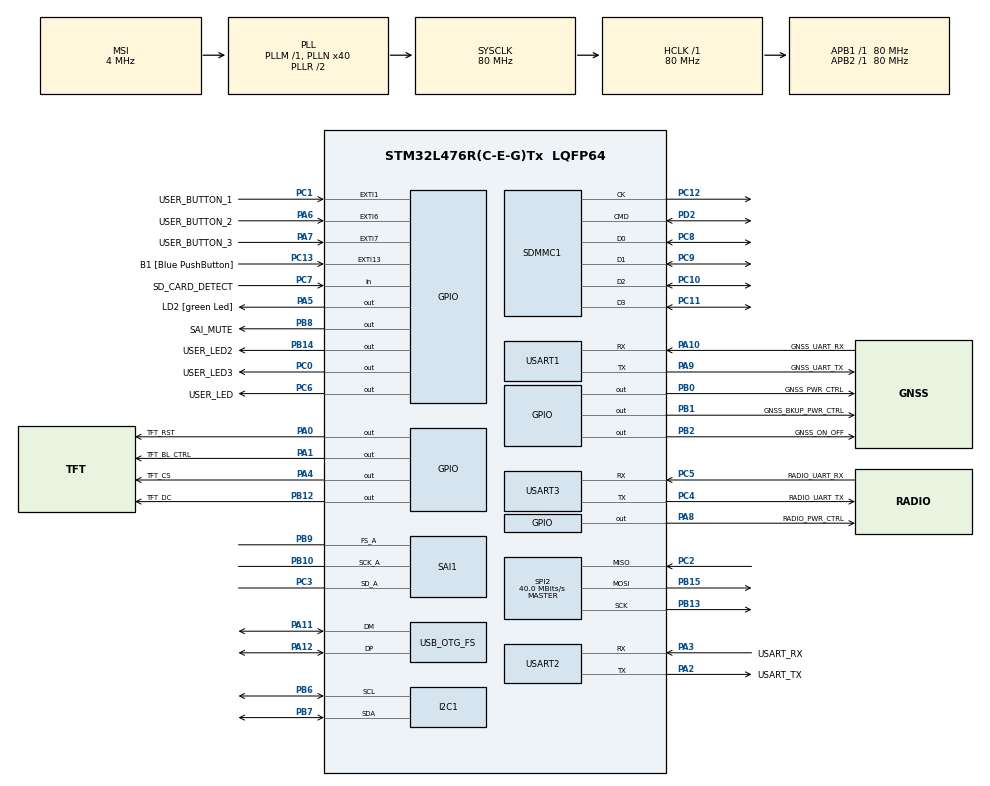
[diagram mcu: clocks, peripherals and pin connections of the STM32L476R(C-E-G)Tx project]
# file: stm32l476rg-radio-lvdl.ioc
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Dma.Request0=SAI1_A
Dma.Request1=SPI2_TX
Dma.Request2=SDMMC1_RX
Dma.SAI1_A.0.Direction=DMA_MEMORY_TO_PERIPH
Dma.SAI1_A.0.Instance=DMA2_Channel1
Dma.SAI1_A.0.MemDataAlignment=DMA_MDATAALIGN_HALFWORD
Dma.SAI1_A.0.MemInc=DMA_MINC_ENABLE
Dma.SAI1_A.0.Mode=DMA_NORMAL
Dma.SAI1_A.0.PeriphDataAlignment=DMA_PDATAALIGN_HALFWORD
Dma.SAI1_A.0.PeriphInc=DMA_PINC_DISABLE
Dma.SAI1_A.0.Priority=DMA_PRIORITY_LOW
Dma.SDMMC1_RX.2.Direction=DMA_PERIPH_TO_MEMORY
Dma.SDMMC1_RX.2.Instance=DMA2_Channel4
Dma.SDMMC1_RX.2.MemDataAlignment=DMA_MDATAALIGN_WORD
Dma.SDMMC1_RX.2.MemInc=DMA_MINC_ENABLE
Dma.SDMMC1_RX.2.Mode=DMA_NORMAL
Dma.SDMMC1_RX.2.PeriphDataAlignment=DMA_PDATAALIGN_WORD
Dma.SDMMC1_RX.2.PeriphInc=DMA_PINC_DISABLE
Dma.SDMMC1_RX.2.Priority=DMA_PRIORITY_LOW
Dma.SPI2_TX.1.Direction=DMA_MEMORY_TO_PERIPH
Dma.SPI2_TX.1.Instance=DMA1_Channel5
Dma.SPI2_TX.1.MemDataAlignment=DMA_MDATAALIGN_BYTE
Dma.SPI2_TX.1.MemInc=DMA_MINC_ENABLE
Dma.SPI2_TX.1.Mode=DMA_NORMAL
Dma.SPI2_TX.1.PeriphDataAlignment=DMA_PDATAALIGN_BYTE
Dma.SPI2_TX.1.PeriphInc=DMA_PINC_DISABLE
Dma.SPI2_TX.1.Priority=DMA_PRIORITY_LOW
FATFS.BSP.number=1
FATFS._USE_LFN=2
FATFS0.BSP.STBoard=false
FATFS0.BSP.api=Unknown
FATFS0.BSP.instance=PC7
FATFS0.BSP.ip=GPIO
FATFS0.BSP.mode=Input
FATFS0.BSP.name=Detect_SDIO
FATFS0.BSP.solution=PC7
FREERTOS.Mutexes01=gnssDataLock,Dynamic,NULL,Depleted;uiDataLock,Dynamic,NULL,Depleted;debugLock,Dynamic,NULL,Depleted;sdCardAccessLock,Dynamic,NULL,Available
FREERTOS.Tasks01=mainTask,24,128,StartDefaultTask,Default,NULL,Dynamic,NULL,NULL;gnssTask,8,128,startGnssTask,Default,NULL,Dynamic,NULL,NULL;uiTask,40,3000,startUiTask,Default,NULL,Dynamic,NULL,NULL
FREERTOS.configMINIMAL_STACK_SIZE=128
FREERTOS.configTOTAL_HEAP_SIZE=20000
FREERTOS.configUSE_NEWLIB_REENTRANT=1
I2C1.Timing=0x10D19CE4
Mcu.Family=STM32L4
Mcu.Name=STM32L476R(C-E-G)Tx
Mcu.Package=LQFP64
NVIC.DMA1_Channel5_IRQn=true\:5\:0\:false\:false\:true\:true\:false\:true\:true
NVIC.DMA2_Channel1_IRQn=true\:5\:0\:false\:false\:true\:true\:false\:true\:true
NVIC.DMA2_Channel4_IRQn=true\:5\:0\:false\:false\:true\:true\:false\:true\:true
NVIC.EXTI15_10_IRQn=true\:5\:0\:false\:false\:true\:true\:true\:true\:true
NVIC.EXTI1_IRQn=true\:5\:0\:false\:false\:true\:true\:true\:true\:true
NVIC.EXTI9_5_IRQn=true\:5\:0\:false\:false\:true\:true\:true\:true\:true
NVIC.OTG_FS_IRQn=true\:5\:0\:false\:false\:true\:true\:false\:true\:true
NVIC.PriorityGroup=NVIC_PRIORITYGROUP_4
NVIC.TIM1_UP_TIM16_IRQn=true\:15\:0\:false\:false\:true\:false\:false\:true\:true
NVIC.TimeBase=TIM1_UP_TIM16_IRQn
NVIC.TimeBaseIP=TIM1
PA0.GPIO_Label=TFT_RST
PA0.Signal=GPIO_Output
PA1.GPIO_Label=TFT_BL_CTRL
PA1.Signal=GPIO_Output
PA10.GPIO_Label=GNSS_UART_RX
PA10.Mode=Asynchronous
PA10.Signal=USART1_RX
PA11.Mode=Device_Only
PA11.Signal=USB_OTG_FS_DM
PA12.Mode=Device_Only
PA12.Signal=USB_OTG_FS_DP
PA13\ (JTMS-SWDIO).GPIO_Label=TMS
PA13\ (JTMS-SWDIO).Mode=Serial_Wire
PA13\ (JTMS-SWDIO).Signal=SYS_JTMS-SWDIO
PA14\ (JTCK-SWCLK).GPIO_Label=TCK
PA14\ (JTCK-SWCLK).Mode=Serial_Wire
PA14\ (JTCK-SWCLK).Signal=SYS_JTCK-SWCLK
PA2.GPIO_Label=USART_TX
PA2.GPIO_Mode=GPIO_MODE_AF_PP
PA2.GPIO_PuPd=GPIO_NOPULL
PA2.GPIO_Speed=GPIO_SPEED_FREQ_VERY_HIGH
PA2.Mode=Asynchronous
PA2.Signal=USART2_TX
PA3.GPIO_Label=USART_RX
PA3.GPIO_Mode=GPIO_MODE_AF_PP
PA3.GPIO_PuPd=GPIO_NOPULL
PA3.GPIO_Speed=GPIO_SPEED_FREQ_VERY_HIGH
PA3.Mode=Asynchronous
PA3.Signal=USART2_RX
PA4.GPIO_Label=TFT_CS
PA4.Signal=GPIO_Output
PA5.GPIO_Label=LD2 [green Led]
PA5.GPIO_ModeDefaultOutputPP=GPIO_MODE_OUTPUT_PP
PA5.GPIO_PuPd=GPIO_NOPULL
PA5.GPIO_Speed=GPIO_SPEED_FREQ_LOW
PA5.Signal=GPIO_Output
PA6.GPIO_Label=USER_BUTTON_2
PA6.Signal=GPXTI6
PA7.GPIO_Label=USER_BUTTON_3
PA7.Signal=GPXTI7
PA8.GPIO_Label=RADIO_PWR_CTRL
PA8.Signal=GPIO_Output
PA9.GPIO_Label=GNSS_UART_TX
PA9.Mode=Asynchronous
PA9.Signal=USART1_TX
PB0.GPIO_Label=GNSS_PWR_CTRL
PB0.Signal=GPIO_Output
PB1.GPIO_Label=GNSS_BKUP_PWR_CTRL
PB1.Signal=GPIO_Output
PB10.Mode=SAI_A_Master
PB10.Signal=SAI1_SCK_A
PB12.GPIO_Label=TFT_DC
PB12.Signal=GPIO_Output
PB13.Mode=Full_Duplex_Master
PB13.Signal=SPI2_SCK
PB14.GPIO_Label=USER_LED2
PB14.Signal=GPIO_Output
PB15.Mode=Full_Duplex_Master
PB15.Signal=SPI2_MOSI
PB2.GPIO_Label=GNSS_ON_OFF
PB2.Signal=GPIO_Output
PB3\ (JTDO-TRACESWO).GPIO_Label=SWO
PB3\ (JTDO-TRACESWO).Signal=SYS_JTDO-SWO
PB6.Mode=I2C
PB6.Signal=I2C1_SCL
PB7.Mode=I2C
PB7.Signal=I2C1_SDA
PB8.GPIO_Label=SAI_MUTE
PB8.Signal=GPIO_Output
PB9.Mode=SAI_A_Master
PB9.Signal=SAI1_FS_A
PC0.GPIO_Label=USER_LED3
PC0.Signal=GPIO_Output
PC1.GPIO_Label=USER_BUTTON_1
PC1.Signal=GPXTI1
PC10.Mode=SD_4_bits_Wide_bus
PC10.Signal=SDMMC1_D2
PC11.Mode=SD_4_bits_Wide_bus
PC11.Signal=SDMMC1_D3
PC12.Mode=SD_4_bits_Wide_bus
PC12.Signal=SDMMC1_CK
PC13.GPIO_Label=B1 [Blue PushButton]
PC13.GPIO_ModeDefaultEXTI=GPIO_MODE_IT_FALLING
PC13.GPIO_PuPd=GPIO_NOPULL
PC13.Signal=GPXTI13
PC14-OSC32_IN\ (PC14).Mode=LSE-External-Oscillator
PC14-OSC32_IN\ (PC14).Signal=RCC_OSC32_IN
PC15-OSC32_OUT\ (PC15).Mode=LSE-External-Oscillator
PC15-OSC32_OUT\ (PC15).Signal=RCC_OSC32_OUT
PC2.Mode=Full_Duplex_Master
PC2.Signal=SPI2_MISO
PC3.Mode=SAI_A_Master
PC3.Signal=SAI1_SD_A
PC4.GPIO_Label=RADIO_UART_TX
PC4.Mode=Asynchronous
PC4.Signal=USART3_TX
PC5.GPIO_Label=RADIO_UART_RX
PC5.Mode=Asynchronous
PC5.Signal=USART3_RX
PC6.GPIO_Label=USER_LED
PC6.Signal=GPIO_Output
PC7.GPIO_Label=SD_CARD_DETECT
PC7.Signal=GPIO_Input
PC8.Mode=SD_4_bits_Wide_bus
PC8.Signal=SDMMC1_D0
PC9.Mode=SD_4_bits_Wide_bus
PC9.Signal=SDMMC1_D1
PD2.Mode=SD_4_bits_Wide_bus
PD2.Signal=SDMMC1_CMD
PH0-OSC_IN\ (PH0).Signal=RCC_OSC_IN
PH1-OSC_OUT\ (PH1).Signal=RCC_OSC_OUT
ProjectManager.HeapSize=0x400
ProjectManager.StackSize=0x800
ProjectManager.TargetToolchain=STM32CubeIDE
RCC.ADCFreq_Value=48000000
RCC.AHBFreq_Value=80000000
RCC.APB1Freq_Value=80000000
RCC.APB1TimFreq_Value=80000000
RCC.APB2Freq_Value=80000000
RCC.APB2TimFreq_Value=80000000
RCC.CortexFreq_Value=80000000
RCC.HCLKFreq_Value=80000000
RCC.HSE_VALUE=8000000
RCC.HSI_VALUE=16000000
RCC.MSI_VALUE=4000000
RCC.PLLN=40
RCC.PLLSAI1N=24
RCC.PLLSAI2N=16
RCC.PREFETCH_ENABLE=1
RCC.SAI1CLockSelection=RCC_SAI1CLKSOURCE_PLLSAI2
RCC.SYSCLKFreq_VALUE=80000000
RCC.SYSCLKSource=RCC_SYSCLKSOURCE_PLLCLK
RCC.USBFreq_Value=48000000
RCC.VCOOutputFreq_Value=160000000
SAI1.AudioFrequency-SAI_A_Master=SAI_AUDIO_FREQUENCY_32K
SAI1.ErrorAudioFreq-SAI_A_Master=-5.83 %
SAI1.InitProtocol-SAI_A_Master=Enable
SAI1.Instance-SAI_A_Master=SAI$Index_Block_A
SAI1.MClockEnable-SAI_A_Master=SAI_MASTERCLOCK_DISABLE
SAI1.NoDivider-SAI_A_Master=SAI_MASTERDIVIDER_ENABLE
SAI1.RealAudioFreq-SAI_A_Master=30.133 KHz
SAI1.VirtualMode-SAI_A_Master=VM_MASTER
SAI1.VirtualProtocol-SAI_A_BASIC=VM_BASIC_PROTOCOL
SDMMC1.ClockDiv=0
SPI2.BaudRatePrescaler=SPI_BAUDRATEPRESCALER_2
SPI2.CLKPolarity=SPI_POLARITY_HIGH
SPI2.CalculateBaudRate=40.0 MBits/s
SPI2.DataSize=SPI_DATASIZE_8BIT
SPI2.Direction=SPI_DIRECTION_2LINES
SPI2.Mode=SPI_MODE_MASTER
SPI2.NSSPMode=SPI_NSS_PULSE_DISABLE
SPI2.VirtualType=VM_MASTER
USART1.VirtualMode-Asynchronous=VM_ASYNC
USART2.VirtualMode-Asynchronous=VM_ASYNC
USART3.VirtualMode-Asynchronous=VM_ASYNC
USB_DEVICE.CLASS_NAME_FS=CDC
USB_DEVICE.VirtualMode=Cdc
USB_DEVICE.VirtualModeFS=Cdc_FS
USB_OTG_FS.VirtualMode=Device_Only
VP_FATFS_VS_SDIO.Mode=SDIO
VP_FREERTOS_VS_CMSIS_V2.Mode=CMSIS_V2
VP_RTC_VS_RTC_Activate.Mode=RTC_Enabled
VP_RTC_VS_RTC_Calendar.Mode=RTC_Calendar
VP_SAI1_VP_$IpInstance_SAIA_SAI_BASIC.Mode=SAI_A_BASIC
VP_SYS_VS_tim1.Mode=TIM1
VP_USB_DEVICE_VS_USB_DEVICE_CDC_FS.Mode=CDC_FS
board=NUCLEO-L476RG

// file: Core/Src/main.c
/* USER CODE BEGIN Header */
/**
 ******************************************************************************
 * @file           : main.c
 * @brief          : Main program body
 ******************************************************************************
 * @attention
 *
 * Copyright (c) 2025 STMicroelectronics.
 * All rights reserved.
 *
 * This software is licensed under terms that can be found in the LICENSE file
 * in the root directory of this software component.
 * If no LICENSE file comes with this software, it is provided AS-IS.
 *
 ******************************************************************************
 */
/* USER CODE END Header */
#include "main.h"
#include "cmsis_os.h"
#include "fatfs.h"
#include "usb_device.h"

/* USER CODE BEGIN Includes */
#include "app.h"
/* USER CODE END Includes */

I2C_HandleTypeDef hi2c1;

RTC_HandleTypeDef hrtc;

SAI_HandleTypeDef hsai_BlockA1;
DMA_HandleTypeDef hdma_sai1_a;

SD_HandleTypeDef hsd1;
DMA_HandleTypeDef hdma_sdmmc1_rx;

SPI_HandleTypeDef hspi2;
DMA_HandleTypeDef hdma_spi2_tx;

UART_HandleTypeDef huart1;
UART_HandleTypeDef huart2;
UART_HandleTypeDef huart3;

/* Definitions for mainTask */
osThreadId_t mainTaskHandle;
const osThreadAttr_t mainTask_attributes = {
  .name = "mainTask",
  .stack_size = 128 * 4,
  .priority = (osPriority_t) osPriorityNormal,
};
/* Definitions for gnssTask */
osThreadId_t gnssTaskHandle;
const osThreadAttr_t gnssTask_attributes = {
  .name = "gnssTask",
  .stack_size = 128 * 4,
  .priority = (osPriority_t) osPriorityLow,
};
/* Definitions for uiTask */
osThreadId_t uiTaskHandle;
const osThreadAttr_t uiTask_attributes = {
  .name = "uiTask",
  .stack_size = 1500 * 4,
  .priority = (osPriority_t) osPriorityHigh,
};
/* Definitions for gnssDataLock */
osMutexId_t gnssDataLockHandle;
const osMutexAttr_t gnssDataLock_attributes = {
  .name = "gnssDataLock"
};
/* Definitions for uiDataLock */
osMutexId_t uiDataLockHandle;
const osMutexAttr_t uiDataLock_attributes = {
  .name = "uiDataLock"
};
/* Definitions for debugLock */
osMutexId_t debugLockHandle;
const osMutexAttr_t debugLock_attributes = {
  .name = "debugLock"
};
/* Definitions for sdCardAccessLock */
osMutexId_t sdCardAccessLockHandle;
const osMutexAttr_t sdCardAccessLock_attributes = {
  .name = "sdCardAccessLock"
};

void SystemClock_Config(void);
void PeriphCommonClock_Config(void);
static void MX_GPIO_Init(void);
static void MX_DMA_Init(void);
static void MX_SAI1_Init(void);
static void MX_USART2_UART_Init(void);
static void MX_SDMMC1_SD_Init(void);
static void MX_SPI2_Init(void);
static void MX_USART1_UART_Init(void);
static void MX_USART3_UART_Init(void);
static void MX_RTC_Init(void);
static void MX_I2C1_Init(void);
void StartDefaultTask(void *argument);
void startGnssTask(void *argument);
void startUiTask(void *argument);

int main(void)
{

  /* MCU Configuration--------------------------------------------------------*/

  /* Reset of all peripherals, Initializes the Flash interface and the Systick. */
  HAL_Init();

  /* Configure the system clock */
  SystemClock_Config();

  /* Configure the peripherals common clocks */
  PeriphCommonClock_Config();

  /* Initialize all configured peripherals */
  MX_GPIO_Init();
  MX_DMA_Init();
  MX_SAI1_Init();
  MX_USART2_UART_Init();
  MX_SDMMC1_SD_Init();
  MX_SPI2_Init();
  MX_FATFS_Init();
  MX_USART1_UART_Init();
  MX_USART3_UART_Init();
  MX_RTC_Init();
  MX_I2C1_Init();

  /* Init scheduler */
  osKernelInitialize();
  /* Create the mutex(es) */
  /* creation of gnssDataLock */
  gnssDataLockHandle = osMutexNew(&gnssDataLock_attributes);

  /* creation of uiDataLock */
  uiDataLockHandle = osMutexNew(&uiDataLock_attributes);

  /* creation of debugLock */
  debugLockHandle = osMutexNew(&debugLock_attributes);

  /* creation of sdCardAccessLock */
  sdCardAccessLockHandle = osMutexNew(&sdCardAccessLock_attributes);

  /* Create the thread(s) */
  /* creation of mainTask */
  mainTaskHandle = osThreadNew(StartDefaultTask, NULL, &mainTask_attributes);

  /* creation of gnssTask */
  gnssTaskHandle = osThreadNew(startGnssTask, NULL, &gnssTask_attributes);

  /* creation of uiTask */
  uiTaskHandle = osThreadNew(startUiTask, NULL, &uiTask_attributes);

  /* Start scheduler */
  osKernelStart();

  /* We should never get here as control is now taken by the scheduler */

  /* Infinite loop */
	while (1) {

	}
}

void SystemClock_Config(void)
{
  RCC_OscInitTypeDef RCC_OscInitStruct = {0};
  RCC_ClkInitTypeDef RCC_ClkInitStruct = {0};

  /** Configure the main internal regulator output voltage
  */
  if (HAL_PWREx_ControlVoltageScaling(PWR_REGULATOR_VOLTAGE_SCALE1) != HAL_OK)
  {
    Error_Handler();
  }

  /** Configure LSE Drive Capability
  */
  HAL_PWR_EnableBkUpAccess();
  __HAL_RCC_LSEDRIVE_CONFIG(RCC_LSEDRIVE_LOW);

  /** Initializes the RCC Oscillators according to the specified parameters
  * in the RCC_OscInitTypeDef structure.
  */
  RCC_OscInitStruct.OscillatorType = RCC_OSCILLATORTYPE_LSI|RCC_OSCILLATORTYPE_LSE
                              |RCC_OSCILLATORTYPE_MSI;
  RCC_OscInitStruct.LSEState = RCC_LSE_ON;
  RCC_OscInitStruct.LSIState = RCC_LSI_ON;
  RCC_OscInitStruct.MSIState = RCC_MSI_ON;
  RCC_OscInitStruct.MSICalibrationValue = 0;
  RCC_OscInitStruct.MSIClockRange = RCC_MSIRANGE_6;
  RCC_OscInitStruct.PLL.PLLState = RCC_PLL_ON;
  RCC_OscInitStruct.PLL.PLLSource = RCC_PLLSOURCE_MSI;
  RCC_OscInitStruct.PLL.PLLM = 1;
  RCC_OscInitStruct.PLL.PLLN = 40;
  RCC_OscInitStruct.PLL.PLLP = RCC_PLLP_DIV7;
  RCC_OscInitStruct.PLL.PLLQ = RCC_PLLQ_DIV2;
  RCC_OscInitStruct.PLL.PLLR = RCC_PLLR_DIV2;
  if (HAL_RCC_OscConfig(&RCC_OscInitStruct) != HAL_OK)
  {
    Error_Handler();
  }

  /** Initializes the CPU, AHB and APB buses clocks
  */
  RCC_ClkInitStruct.ClockType = RCC_CLOCKTYPE_HCLK|RCC_CLOCKTYPE_SYSCLK
                              |RCC_CLOCKTYPE_PCLK1|RCC_CLOCKTYPE_PCLK2;
  RCC_ClkInitStruct.SYSCLKSource = RCC_SYSCLKSOURCE_PLLCLK;
  RCC_ClkInitStruct.AHBCLKDivider = RCC_SYSCLK_DIV1;
  RCC_ClkInitStruct.APB1CLKDivider = RCC_HCLK_DIV1;
  RCC_ClkInitStruct.APB2CLKDivider = RCC_HCLK_DIV1;

  if (HAL_RCC_ClockConfig(&RCC_ClkInitStruct, FLASH_LATENCY_4) != HAL_OK)
  {
    Error_Handler();
  }

  /** Enable MSI Auto calibration
  */
  HAL_RCCEx_EnableMSIPLLMode();
}

void PeriphCommonClock_Config(void)
{
  RCC_PeriphCLKInitTypeDef PeriphClkInit = {0};

  /** Initializes the peripherals clock
  */
  PeriphClkInit.PeriphClockSelection = RCC_PERIPHCLK_USB|RCC_PERIPHCLK_SDMMC1;
  PeriphClkInit.UsbClockSelection = RCC_USBCLKSOURCE_PLLSAI1;
  PeriphClkInit.Sdmmc1ClockSelection = RCC_SDMMC1CLKSOURCE_PLLSAI1;
  PeriphClkInit.PLLSAI1.PLLSAI1Source = RCC_PLLSOURCE_MSI;
  PeriphClkInit.PLLSAI1.PLLSAI1M = 1;
  PeriphClkInit.PLLSAI1.PLLSAI1N = 24;
  PeriphClkInit.PLLSAI1.PLLSAI1P = RCC_PLLP_DIV7;
  PeriphClkInit.PLLSAI1.PLLSAI1Q = RCC_PLLQ_DIV2;
  PeriphClkInit.PLLSAI1.PLLSAI1R = RCC_PLLR_DIV2;
  PeriphClkInit.PLLSAI1.PLLSAI1ClockOut = RCC_PLLSAI1_48M2CLK;
  if (HAL_RCCEx_PeriphCLKConfig(&PeriphClkInit) != HAL_OK)
  {
    Error_Handler();
  }
}

static void MX_I2C1_Init(void)
{

  hi2c1.Instance = I2C1;
  hi2c1.Init.Timing = 0x10D19CE4;
  hi2c1.Init.OwnAddress1 = 0;
  hi2c1.Init.AddressingMode = I2C_ADDRESSINGMODE_7BIT;
  hi2c1.Init.DualAddressMode = I2C_DUALADDRESS_DISABLE;
  hi2c1.Init.OwnAddress2 = 0;
  hi2c1.Init.OwnAddress2Masks = I2C_OA2_NOMASK;
  hi2c1.Init.GeneralCallMode = I2C_GENERALCALL_DISABLE;
  hi2c1.Init.NoStretchMode = I2C_NOSTRETCH_DISABLE;
  if (HAL_I2C_Init(&hi2c1) != HAL_OK)
  {
    Error_Handler();
  }

  /** Configure Analogue filter
  */
  if (HAL_I2CEx_ConfigAnalogFilter(&hi2c1, I2C_ANALOGFILTER_ENABLE) != HAL_OK)
  {
    Error_Handler();
  }

  /** Configure Digital filter
  */
  if (HAL_I2CEx_ConfigDigitalFilter(&hi2c1, 0) != HAL_OK)
  {
    Error_Handler();
  }

}

static void MX_RTC_Init(void)
{

  RTC_TimeTypeDef sTime = {0};
  RTC_DateTypeDef sDate = {0};

  /** Initialize RTC Only
  */
  hrtc.Instance = RTC;
  hrtc.Init.HourFormat = RTC_HOURFORMAT_24;
  hrtc.Init.AsynchPrediv = 127;
  hrtc.Init.SynchPrediv = 255;
  hrtc.Init.OutPut = RTC_OUTPUT_DISABLE;
  hrtc.Init.OutPutRemap = RTC_OUTPUT_REMAP_NONE;
  hrtc.Init.OutPutPolarity = RTC_OUTPUT_POLARITY_HIGH;
  hrtc.Init.OutPutType = RTC_OUTPUT_TYPE_OPENDRAIN;
  if (HAL_RTC_Init(&hrtc) != HAL_OK)
  {
    Error_Handler();
  }

  /** Initialize RTC and set the Time and Date
  */
  sTime.Hours = 0x0;
  sTime.Minutes = 0x0;
  sTime.Seconds = 0x0;
  sTime.DayLightSaving = RTC_DAYLIGHTSAVING_NONE;
  sTime.StoreOperation = RTC_STOREOPERATION_RESET;
  if (HAL_RTC_SetTime(&hrtc, &sTime, RTC_FORMAT_BCD) != HAL_OK)
  {
    Error_Handler();
  }
  sDate.WeekDay = RTC_WEEKDAY_MONDAY;
  sDate.Month = RTC_MONTH_JANUARY;
  sDate.Date = 0x1;
  sDate.Year = 0x0;

  if (HAL_RTC_SetDate(&hrtc, &sDate, RTC_FORMAT_BCD) != HAL_OK)
  {
    Error_Handler();
  }

}

static void MX_SAI1_Init(void)
{

  hsai_BlockA1.Instance = SAI1_Block_A;
  hsai_BlockA1.Init.AudioMode = SAI_MODEMASTER_TX;
  hsai_BlockA1.Init.Synchro = SAI_ASYNCHRONOUS;
  hsai_BlockA1.Init.OutputDrive = SAI_OUTPUTDRIVE_DISABLE;
  hsai_BlockA1.Init.NoDivider = SAI_MASTERDIVIDER_ENABLE;
  hsai_BlockA1.Init.FIFOThreshold = SAI_FIFOTHRESHOLD_EMPTY;
  hsai_BlockA1.Init.AudioFrequency = SAI_AUDIO_FREQUENCY_32K;
  hsai_BlockA1.Init.SynchroExt = SAI_SYNCEXT_DISABLE;
  hsai_BlockA1.Init.MonoStereoMode = SAI_STEREOMODE;
  hsai_BlockA1.Init.CompandingMode = SAI_NOCOMPANDING;
  hsai_BlockA1.Init.TriState = SAI_OUTPUT_NOTRELEASED;
  if (HAL_SAI_InitProtocol(&hsai_BlockA1, SAI_I2S_STANDARD, SAI_PROTOCOL_DATASIZE_16BIT, 2) != HAL_OK)
  {
    Error_Handler();
  }

}

static void MX_SDMMC1_SD_Init(void)
{

  hsd1.Instance = SDMMC1;
  hsd1.Init.ClockEdge = SDMMC_CLOCK_EDGE_RISING;
  hsd1.Init.ClockBypass = SDMMC_CLOCK_BYPASS_DISABLE;
  hsd1.Init.ClockPowerSave = SDMMC_CLOCK_POWER_SAVE_DISABLE;
  hsd1.Init.BusWide = SDMMC_BUS_WIDE_4B;
  hsd1.Init.HardwareFlowControl = SDMMC_HARDWARE_FLOW_CONTROL_DISABLE;
  hsd1.Init.ClockDiv = 0;

}

static void MX_SPI2_Init(void)
{

  /* SPI2 parameter configuration*/
  hspi2.Instance = SPI2;
  hspi2.Init.Mode = SPI_MODE_MASTER;
  hspi2.Init.Direction = SPI_DIRECTION_2LINES;
  hspi2.Init.DataSize = SPI_DATASIZE_8BIT;
  hspi2.Init.CLKPolarity = SPI_POLARITY_HIGH;
  hspi2.Init.CLKPhase = SPI_PHASE_1EDGE;
  hspi2.Init.NSS = SPI_NSS_SOFT;
  hspi2.Init.BaudRatePrescaler = SPI_BAUDRATEPRESCALER_2;
  hspi2.Init.FirstBit = SPI_FIRSTBIT_MSB;
  hspi2.Init.TIMode = SPI_TIMODE_DISABLE;
  hspi2.Init.CRCCalculation = SPI_CRCCALCULATION_DISABLE;
  hspi2.Init.CRCPolynomial = 7;
  hspi2.Init.CRCLength = SPI_CRC_LENGTH_DATASIZE;
  hspi2.Init.NSSPMode = SPI_NSS_PULSE_DISABLE;
  if (HAL_SPI_Init(&hspi2) != HAL_OK)
  {
    Error_Handler();
  }

}

static void MX_USART1_UART_Init(void)
{

  huart1.Instance = USART1;
  huart1.Init.BaudRate = 115200;
  huart1.Init.WordLength = UART_WORDLENGTH_8B;
  huart1.Init.StopBits = UART_STOPBITS_1;
  huart1.Init.Parity = UART_PARITY_NONE;
  huart1.Init.Mode = UART_MODE_TX_RX;
  huart1.Init.HwFlowCtl = UART_HWCONTROL_NONE;
  huart1.Init.OverSampling = UART_OVERSAMPLING_16;
  huart1.Init.OneBitSampling = UART_ONE_BIT_SAMPLE_DISABLE;
  huart1.AdvancedInit.AdvFeatureInit = UART_ADVFEATURE_NO_INIT;
  if (HAL_UART_Init(&huart1) != HAL_OK)
  {
    Error_Handler();
  }

}

static void MX_USART2_UART_Init(void)
{

  huart2.Instance = USART2;
  huart2.Init.BaudRate = 115200;
  huart2.Init.WordLength = UART_WORDLENGTH_8B;
  huart2.Init.StopBits = UART_STOPBITS_1;
  huart2.Init.Parity = UART_PARITY_NONE;
  huart2.Init.Mode = UART_MODE_TX_RX;
  huart2.Init.HwFlowCtl = UART_HWCONTROL_NONE;
  huart2.Init.OverSampling = UART_OVERSAMPLING_16;
  huart2.Init.OneBitSampling = UART_ONE_BIT_SAMPLE_DISABLE;
  huart2.AdvancedInit.AdvFeatureInit = UART_ADVFEATURE_NO_INIT;
  if (HAL_UART_Init(&huart2) != HAL_OK)
  {
    Error_Handler();
  }

}

static void MX_USART3_UART_Init(void)
{

  huart3.Instance = USART3;
  huart3.Init.BaudRate = 115200;
  huart3.Init.WordLength = UART_WORDLENGTH_8B;
  huart3.Init.StopBits = UART_STOPBITS_1;
  huart3.Init.Parity = UART_PARITY_NONE;
  huart3.Init.Mode = UART_MODE_TX_RX;
  huart3.Init.HwFlowCtl = UART_HWCONTROL_NONE;
  huart3.Init.OverSampling = UART_OVERSAMPLING_16;
  huart3.Init.OneBitSampling = UART_ONE_BIT_SAMPLE_DISABLE;
  huart3.AdvancedInit.AdvFeatureInit = UART_ADVFEATURE_NO_INIT;
  if (HAL_UART_Init(&huart3) != HAL_OK)
  {
    Error_Handler();
  }

}

static void MX_DMA_Init(void)
{

  /* DMA controller clock enable */
  __HAL_RCC_DMA2_CLK_ENABLE();
  __HAL_RCC_DMA1_CLK_ENABLE();

  /* DMA interrupt init */
  /* DMA1_Channel5_IRQn interrupt configuration */
  HAL_NVIC_SetPriority(DMA1_Channel5_IRQn, 5, 0);
  HAL_NVIC_EnableIRQ(DMA1_Channel5_IRQn);
  /* DMA2_Channel1_IRQn interrupt configuration */
  HAL_NVIC_SetPriority(DMA2_Channel1_IRQn, 5, 0);
  HAL_NVIC_EnableIRQ(DMA2_Channel1_IRQn);
  /* DMA2_Channel4_IRQn interrupt configuration */
  HAL_NVIC_SetPriority(DMA2_Channel4_IRQn, 5, 0);
  HAL_NVIC_EnableIRQ(DMA2_Channel4_IRQn);

}

static void MX_GPIO_Init(void)
{
  GPIO_InitTypeDef GPIO_InitStruct = {0};

  /* GPIO Ports Clock Enable */
  __HAL_RCC_GPIOC_CLK_ENABLE();
  __HAL_RCC_GPIOH_CLK_ENABLE();
  __HAL_RCC_GPIOA_CLK_ENABLE();
  __HAL_RCC_GPIOB_CLK_ENABLE();
  __HAL_RCC_GPIOD_CLK_ENABLE();

  /*Configure GPIO pin Output Level */
  HAL_GPIO_WritePin(GPIOC, USER_LED3_Pin|USER_LED_Pin, GPIO_PIN_RESET);

  /*Configure GPIO pin Output Level */
  HAL_GPIO_WritePin(GPIOA, TFT_RST_Pin|TFT_BL_CTRL_Pin|TFT_CS_Pin|LD2_Pin
                          |RADIO_PWR_CTRL_Pin, GPIO_PIN_RESET);

  /*Configure GPIO pin Output Level */
  HAL_GPIO_WritePin(GPIOB, GNSS_PWR_CTRL_Pin|GNSS_BKUP_PWR_CTRL_Pin|GNSS_ON_OFF_Pin|TFT_DC_Pin
                          |USER_LED2_Pin|SAI_MUTE_Pin, GPIO_PIN_RESET);

  /*Configure GPIO pin : B1_Pin */
  GPIO_InitStruct.Pin = B1_Pin;
  GPIO_InitStruct.Mode = GPIO_MODE_IT_FALLING;
  GPIO_InitStruct.Pull = GPIO_NOPULL;
  HAL_GPIO_Init(B1_GPIO_Port, &GPIO_InitStruct);

  /*Configure GPIO pins : USER_LED3_Pin USER_LED_Pin */
  GPIO_InitStruct.Pin = USER_LED3_Pin|USER_LED_Pin;
  GPIO_InitStruct.Mode = GPIO_MODE_OUTPUT_PP;
  GPIO_InitStruct.Pull = GPIO_NOPULL;
  GPIO_InitStruct.Speed = GPIO_SPEED_FREQ_LOW;
  HAL_GPIO_Init(GPIOC, &GPIO_InitStruct);

  /*Configure GPIO pin : USER_BUTTON_1_Pin */
  GPIO_InitStruct.Pin = USER_BUTTON_1_Pin;
  GPIO_InitStruct.Mode = GPIO_MODE_IT_RISING;
  GPIO_InitStruct.Pull = GPIO_NOPULL;
  HAL_GPIO_Init(USER_BUTTON_1_GPIO_Port, &GPIO_InitStruct);

  /*Configure GPIO pins : TFT_RST_Pin TFT_BL_CTRL_Pin TFT_CS_Pin LD2_Pin
                           RADIO_PWR_CTRL_Pin */
  GPIO_InitStruct.Pin = TFT_RST_Pin|TFT_BL_CTRL_Pin|TFT_CS_Pin|LD2_Pin
                          |RADIO_PWR_CTRL_Pin;
  GPIO_InitStruct.Mode = GPIO_MODE_OUTPUT_PP;
  GPIO_InitStruct.Pull = GPIO_NOPULL;
  GPIO_InitStruct.Speed = GPIO_SPEED_FREQ_LOW;
  HAL_GPIO_Init(GPIOA, &GPIO_InitStruct);

  /*Configure GPIO pins : USER_BUTTON_2_Pin USER_BUTTON_3_Pin */
  GPIO_InitStruct.Pin = USER_BUTTON_2_Pin|USER_BUTTON_3_Pin;
  GPIO_InitStruct.Mode = GPIO_MODE_IT_RISING;
  GPIO_InitStruct.Pull = GPIO_NOPULL;
  HAL_GPIO_Init(GPIOA, &GPIO_InitStruct);

  /*Configure GPIO pins : GNSS_PWR_CTRL_Pin GNSS_BKUP_PWR_CTRL_Pin GNSS_ON_OFF_Pin TFT_DC_Pin
                           USER_LED2_Pin SAI_MUTE_Pin */
  GPIO_InitStruct.Pin = GNSS_PWR_CTRL_Pin|GNSS_BKUP_PWR_CTRL_Pin|GNSS_ON_OFF_Pin|TFT_DC_Pin
                          |USER_LED2_Pin|SAI_MUTE_Pin;
  GPIO_InitStruct.Mode = GPIO_MODE_OUTPUT_PP;
  GPIO_InitStruct.Pull = GPIO_NOPULL;
  GPIO_InitStruct.Speed = GPIO_SPEED_FREQ_LOW;
  HAL_GPIO_Init(GPIOB, &GPIO_InitStruct);

  /*Configure GPIO pin : SD_CARD_DETECT_Pin */
  GPIO_InitStruct.Pin = SD_CARD_DETECT_Pin;
  GPIO_InitStruct.Mode = GPIO_MODE_INPUT;
  GPIO_InitStruct.Pull = GPIO_NOPULL;
  HAL_GPIO_Init(SD_CARD_DETECT_GPIO_Port, &GPIO_InitStruct);

  /* EXTI interrupt init*/
  HAL_NVIC_SetPriority(EXTI1_IRQn, 5, 0);
  HAL_NVIC_EnableIRQ(EXTI1_IRQn);

  HAL_NVIC_SetPriority(EXTI9_5_IRQn, 5, 0);
  HAL_NVIC_EnableIRQ(EXTI9_5_IRQn);

  HAL_NVIC_SetPriority(EXTI15_10_IRQn, 5, 0);
  HAL_NVIC_EnableIRQ(EXTI15_10_IRQn);

}

void StartDefaultTask(void *argument)
{
  /* init code for USB_DEVICE */
  MX_USB_DEVICE_Init();
  /* USER CODE BEGIN 5 */
	main_app_setup();
	/* Infinite loop */
	for (;;) {
		main_app_update();
	}
  /* USER CODE END 5 */
}

void startGnssTask(void *argument)
{
  /* USER CODE BEGIN startGnssTask */
	//gnss_app_setup();
	/* Infinite loop */
	for (;;) {
		//gnss_app_update();
		osDelay(10);
	}
  /* USER CODE END startGnssTask */
}

void startUiTask(void *argument)
{
  /* USER CODE BEGIN startUiTask */
	ui_app_setup();

	/* Infinite loop */
	for (;;) {
		ui_app_update();
	}
  /* USER CODE END startUiTask */
}

void HAL_TIM_PeriodElapsedCallback(TIM_HandleTypeDef *htim)
{
  if (htim->Instance == TIM1) {
    HAL_IncTick();
  }
}

void Error_Handler(void)
{
	__disable_irq();
	while (1) {
	}
}
